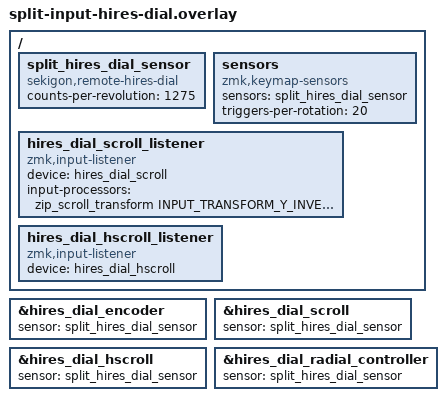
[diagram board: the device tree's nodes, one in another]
#include <dt-bindings/zmk/input_transform.h>

/ {
    /* Split HIRES events use sensor index 0; this device never emits local events. */
    split_hires_dial_sensor: split_hires_dial_sensor {
        compatible = "sekigon,remote-hires-dial";
        counts-per-revolution = <1275>;
    };

    sensors {
        compatible = "zmk,keymap-sensors";
        sensors = <&split_hires_dial_sensor>;
        triggers-per-rotation = <20>;
    };

    hires_dial_scroll_listener {
        compatible = "zmk,input-listener";
        device = <&hires_dial_scroll>;
        /* Clockwise scrolls down, counter-clockwise scrolls up. Only vertical
         * scrolling is flipped; the sensor's own `invert` would also flip the
         * encoder and Radial Controller layers. zip_scroll_transform comes from
         * input/processors.dtsi, included by the right shield overlay. */
        input-processors = <&zip_scroll_transform INPUT_TRANSFORM_Y_INVERT>;
    };

    hires_dial_hscroll_listener {
        compatible = "zmk,input-listener";
        device = <&hires_dial_hscroll>;
    };
};

&hires_dial_encoder {
    sensor = <&split_hires_dial_sensor>;
};

&hires_dial_scroll {
    sensor = <&split_hires_dial_sensor>;
};

&hires_dial_hscroll {
    sensor = <&split_hires_dial_sensor>;
};

&hires_dial_radial_controller {
    sensor = <&split_hires_dial_sensor>;
};
